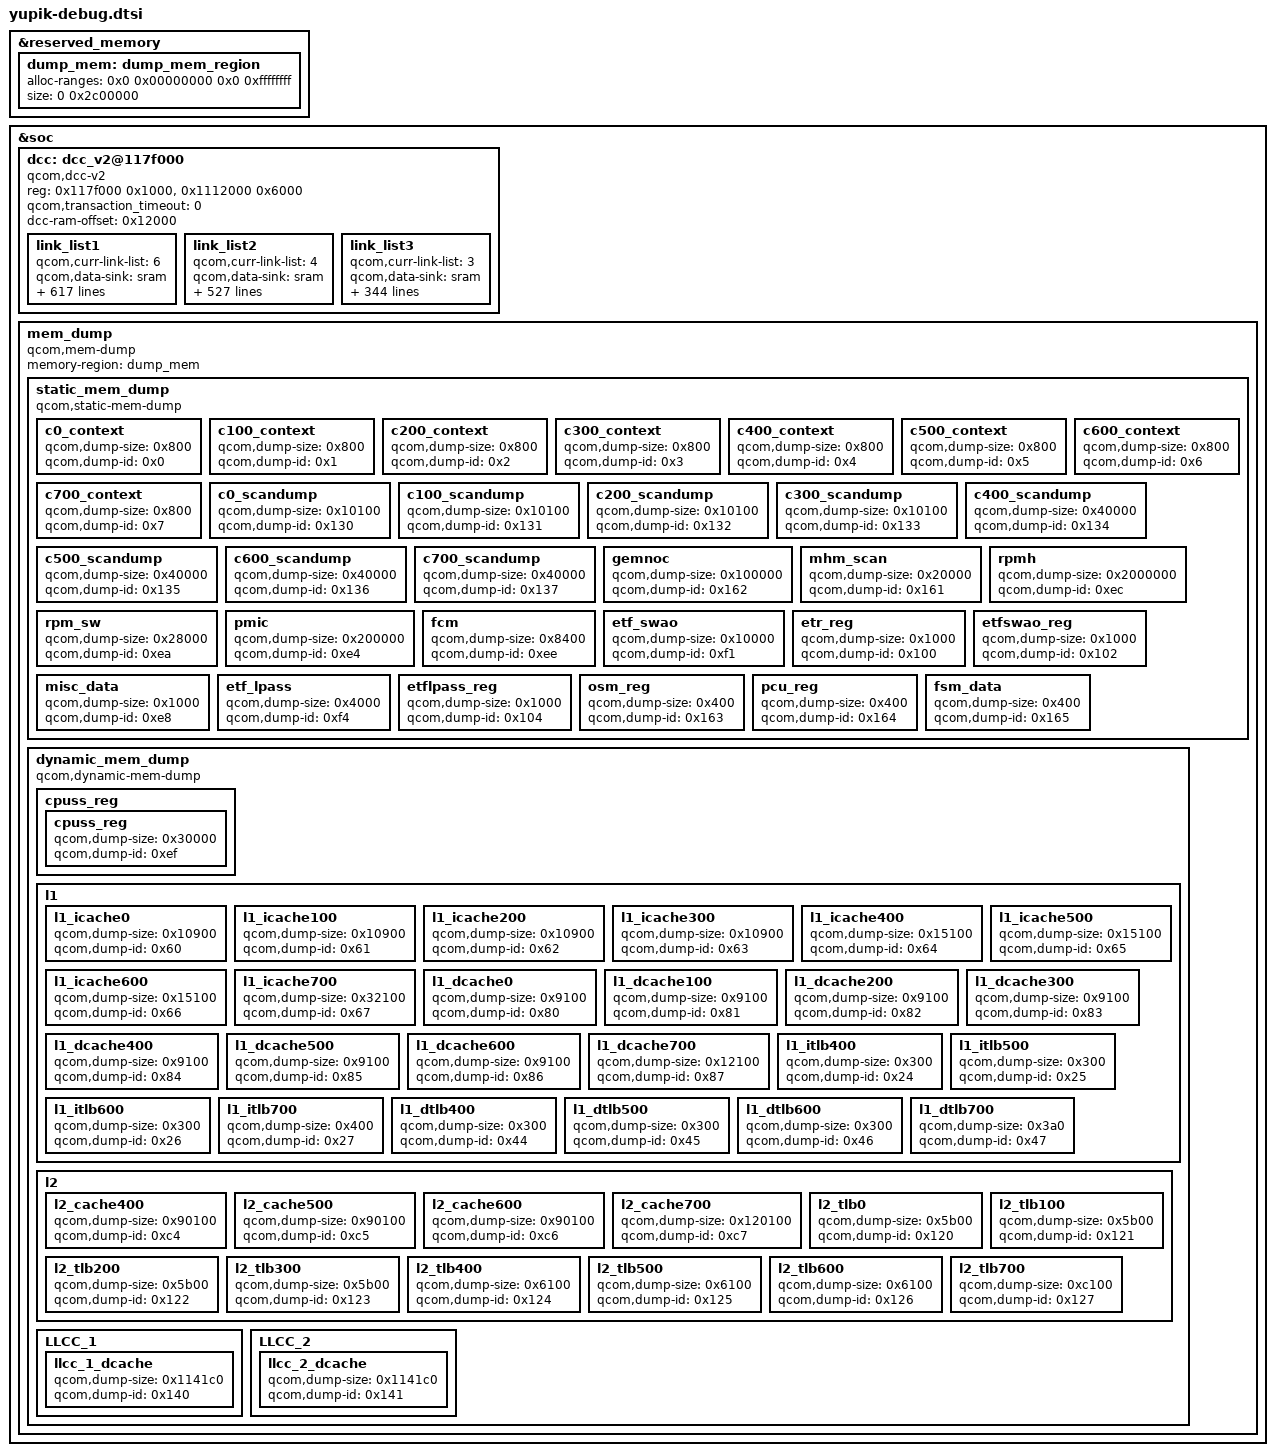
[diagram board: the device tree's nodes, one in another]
// SPDX-License-Identifier: BSD-3-Clause
/*
 * Copyright (c) Qualcomm Technologies, Inc. and/or its subsidiaries.
 */

#include <dt-bindings/soc/qcom,dcc_v2.h>

&reserved_memory {
	#address-cells = <2>;
	#size-cells = <2>;
	ranges;

	dump_mem: dump_mem_region {
		alloc-ranges = <0x0 0x00000000 0x0 0xffffffff>;
		size = <0 0x2c00000>;
	};
};

&soc {
	dcc: dcc_v2@117f000 {
		compatible = "qcom,dcc-v2";
		reg = <0x117f000 0x1000>,
		      <0x1112000 0x6000>;

		qcom,transaction_timeout = <0>;

		reg-names = "dcc-base", "dcc-ram-base";
		dcc-ram-offset = <0x12000>;

		link_list1 {
			qcom,curr-link-list = <6>;
			qcom,data-sink = "sram";
			qcom,link-list = <DCC_READ 0x18000010 1 0>,
				<DCC_READ 0x18000024 1 0>,
				<DCC_READ 0x18000038 6 0>,
				<DCC_READ 0x18010010 1 0>,
				<DCC_READ 0x18010024 1 0>,
				<DCC_READ 0x18010038 6 0>,
				<DCC_READ 0x18020010 1 0>,
				<DCC_READ 0x18020024 1 0>,
				<DCC_READ 0x18020038 6 0>,
				<DCC_READ 0x18030010 1 0>,
				<DCC_READ 0x18030024 1 0>,
				<DCC_READ 0x18030038 6 0>,
				<DCC_READ 0x18040010 1 0>,
				<DCC_READ 0x18040024 1 0>,
				<DCC_READ 0x18040038 6 0>,
				<DCC_READ 0x18050010 1 0>,
				<DCC_READ 0x18050024 1 0>,
				<DCC_READ 0x18050038 6 0>,
				<DCC_READ 0x18060010 1 0>,
				<DCC_READ 0x18060024 1 0>,
				<DCC_READ 0x18060038 6 0>,
				<DCC_READ 0x18070010 1 0>,
				<DCC_READ 0x18070024 1 0>,
				<DCC_READ 0x18070038 6 0>,
				<DCC_READ 0x18080010 1 0>,
				<DCC_READ 0x18080024 1 0>,
				<DCC_READ 0x18080038 6 0>,
				<DCC_READ 0x1808006c 5 0>,
				<DCC_READ 0x18080084 1 0>,
				<DCC_READ 0x180800f4 1 0>,
				<DCC_READ 0x180800f8 1 0>,
				<DCC_READ 0x180800fc 1 0>,
				<DCC_READ 0x18080100 12 0>,
				<DCC_READ 0x18080130 3 0>,
				<DCC_READ 0x18080158 1 0>,
				<DCC_READ 0x1808015c 1 0>,
				<DCC_READ 0x18080160 1 0>,
				<DCC_READ 0x18080164 1 0>,
				<DCC_READ 0x18080168 1 0>,
				<DCC_READ 0x18080170 1 0>,
				<DCC_READ 0x18080174 1 0>,
				<DCC_READ 0x18080188 1 0>,
				<DCC_READ 0x1808018c 1 0>,
				<DCC_READ 0x18080190 1 0>,
				<DCC_READ 0x18080194 1 0>,
				<DCC_READ 0x18080198 1 0>,
				<DCC_READ 0x180801ac 1 0>,
				<DCC_READ 0x180801b0 4 0>,
				<DCC_READ 0x180801c0 1 0>,
				<DCC_READ 0x180801c8 1 0>,
				<DCC_READ 0x180801f0 1 0>,
				<DCC_READ 0x18598020 1 0>,
				<DCC_READ 0x1859001c 1 0>,
				<DCC_READ 0x18590020 1 0>,
				<DCC_READ 0x1859002c 1 0>,
				<DCC_READ 0x18590064 1 0>,
				<DCC_READ 0x18590068 1 0>,
				<DCC_READ 0x1859006c 1 0>,
				<DCC_READ 0x18590070 3 0>,
				<DCC_READ 0x1859008c 1 0>,
				<DCC_READ 0x185900dc 1 0>,
				<DCC_READ 0x185900e8 1 0>,
				<DCC_READ 0x185900ec 1 0>,
				<DCC_READ 0x185900f0 1 0>,
				<DCC_READ 0x18590300 1 0>,
				<DCC_READ 0x1859030c 1 0>,
				<DCC_READ 0x18590320 1 0>,
				<DCC_READ 0x1859034c 1 0>,
				<DCC_READ 0x185903bc 1 0>,
				<DCC_READ 0x185903c0 1 0>,
				<DCC_READ 0x1859101c 1 0>,
				<DCC_READ 0x18591020 1 0>,
				<DCC_READ 0x1859102c 1 0>,
				<DCC_READ 0x18591064 1 0>,
				<DCC_READ 0x18591068 1 0>,
				<DCC_READ 0x1859106c 1 0>,
				<DCC_READ 0x18591070 1 0>,
				<DCC_READ 0x18591074 1 0>,
				<DCC_READ 0x18591078 1 0>,
				<DCC_READ 0x1859108c 1 0>,
				<DCC_READ 0x185910dc 1 0>,
				<DCC_READ 0x185910e8 1 0>,
				<DCC_READ 0x185910ec 1 0>,
				<DCC_READ 0x185910f0 1 0>,
				<DCC_READ 0x18591300 1 0>,
				<DCC_READ 0x1859130c 1 0>,
				<DCC_READ 0x18591320 1 0>,
				<DCC_READ 0x1859134c 1 0>,
				<DCC_READ 0x185913bc 1 0>,
				<DCC_READ 0x185913c0 1 0>,
				<DCC_READ 0x1859201c 1 0>,
				<DCC_READ 0x18592020 1 0>,
				<DCC_READ 0x1859202c 1 0>,
				<DCC_READ 0x18592064 1 0>,
				<DCC_READ 0x18592068 1 0>,
				<DCC_READ 0x1859206c 1 0>,
				<DCC_READ 0x18592070 1 0>,
				<DCC_READ 0x18592074 1 0>,
				<DCC_READ 0x18592078 1 0>,
				<DCC_READ 0x1859208c 1 0>,
				<DCC_READ 0x185920dc 1 0>,
				<DCC_READ 0x185920e8 1 0>,
				<DCC_READ 0x185920ec 1 0>,
				<DCC_READ 0x185920f0 1 0>,
				<DCC_READ 0x18592300 1 0>,
				<DCC_READ 0x1859230c 1 0>,
				<DCC_READ 0x18592320 1 0>,
				<DCC_READ 0x1859234c 1 0>,
				<DCC_READ 0x185923bc 1 0>,
				<DCC_READ 0x185923c0 1 0>,
				<DCC_READ 0x1859301c 1 0>,
				<DCC_READ 0x18593020 1 0>,
				<DCC_READ 0x18593064 1 0>,
				<DCC_READ 0x18593068 1 0>,
				<DCC_READ 0x1859306c 1 0>,
				<DCC_READ 0x18593070 1 0>,
				<DCC_READ 0x18593074 1 0>,
				<DCC_READ 0x18593078 1 0>,
				<DCC_READ 0x1859308c 1 0>,
				<DCC_READ 0x185930dc 1 0>,
				<DCC_READ 0x185930e8 1 0>,
				<DCC_READ 0x185930ec 1 0>,
				<DCC_READ 0x185930f0 1 0>,
				<DCC_READ 0x18593300 1 0>,
				<DCC_READ 0x1859330c 1 0>,
				<DCC_READ 0x18593320 1 0>,
				<DCC_READ 0x1859302c 1 0>,
				<DCC_READ 0x1859334c 1 0>,
				<DCC_READ 0x185933bc 1 0>,
				<DCC_READ 0x185933c0 1 0>,
				<DCC_READ 0x18300000 1 0>,
				<DCC_READ 0x1830000c 1 0>,
				<DCC_READ 0x18300018 1 0>,
				<DCC_READ 0x17c21000 2 0>,
				<DCC_READ 0x18393a84 2 0>,
				<DCC_READ 0x183a3a84 2 0>,
				<DCC_READ 0x18280000 2 0>,
				<DCC_READ 0x18282000 2 0>,
				<DCC_READ 0x18284000 2 0>,
				<DCC_READ 0x18286000 2 0>,
				<DCC_READ 0x18300000 1 0>,
				<DCC_READ 0x18200400 3 0>,
				<DCC_READ 0x18200038 1 0>,
				<DCC_READ 0x18200040 1 0>,
				<DCC_READ 0x18200048 1 0>,
				<DCC_READ 0x18220038 1 0>,
				<DCC_READ 0x18220040 1 0>,
				<DCC_READ 0x182200d0 1 0>,
				<DCC_READ 0x18200030 1 0>,
				<DCC_READ 0x18200010 1 0>,
				<DCC_READ 0x610100 11 0>,
				<DCC_READ 0x18000058 1 0>,
				<DCC_READ 0x1800005c 1 0>,
				<DCC_READ 0x18000060 1 0>,
				<DCC_READ 0x18000064 1 0>,
				<DCC_READ 0x1800006c 1 0>,
				<DCC_READ 0x180000f0 2 0>,
				<DCC_READ 0x18010058 1 0>,
				<DCC_READ 0x1801005c 1 0>,
				<DCC_READ 0x18010060 1 0>,
				<DCC_READ 0x18010064 1 0>,
				<DCC_READ 0x1801006c 1 0>,
				<DCC_READ 0x180100f0 2 0>,
				<DCC_READ 0x18020058 1 0>,
				<DCC_READ 0x1802005c 1 0>,
				<DCC_READ 0x18020060 1 0>,
				<DCC_READ 0x18020064 1 0>,
				<DCC_READ 0x1802006c 1 0>,
				<DCC_READ 0x180200f0 2 0>,
				<DCC_READ 0x18030058 1 0>,
				<DCC_READ 0x1803005c 1 0>,
				<DCC_READ 0x18030060 1 0>,
				<DCC_READ 0x18030064 1 0>,
				<DCC_READ 0x1803006c 1 0>,
				<DCC_READ 0x180300f0 2 0>,
				<DCC_READ 0x18040058 1 0>,
				<DCC_READ 0x1804005c 1 0>,
				<DCC_READ 0x18040060 1 0>,
				<DCC_READ 0x18040064 1 0>,
				<DCC_READ 0x1804006c 1 0>,
				<DCC_READ 0x180400f0 2 0>,
				<DCC_READ 0x18050058 1 0>,
				<DCC_READ 0x1805005c 1 0>,
				<DCC_READ 0x18050060 1 0>,
				<DCC_READ 0x18050064 1 0>,
				<DCC_READ 0x1805006c 1 0>,
				<DCC_READ 0x180500f0 2 0>,
				<DCC_READ 0x18060058 1 0>,
				<DCC_READ 0x1806005c 1 0>,
				<DCC_READ 0x18060060 1 0>,
				<DCC_READ 0x18060064 1 0>,
				<DCC_READ 0x1806006c 1 0>,
				<DCC_READ 0x180600f0 2 0>,
				<DCC_READ 0x18070058 1 0>,
				<DCC_READ 0x1807005c 1 0>,
				<DCC_READ 0x18070060 1 0>,
				<DCC_READ 0x18070064 1 0>,
				<DCC_READ 0x1807006c 1 0>,
				<DCC_READ 0x180700f0 2 0>,
				<DCC_READ 0x18101908 1 0>,
				<DCC_READ 0x18101c18 1 0>,
				<DCC_READ 0x18390810 1 0>,
				<DCC_READ 0x18390c50 1 0>,
				<DCC_READ 0x18390814 1 0>,
				<DCC_READ 0x18390c54 1 0>,
				<DCC_READ 0x18390818 1 0>,
				<DCC_READ 0x18390c58 1 0>,
				<DCC_READ 0x18393a84 2 0>,
				<DCC_READ 0x18100908 1 0>,
				<DCC_READ 0x18100c18 1 0>,
				<DCC_READ 0x183a0810 1 0>,
				<DCC_READ 0x183a0c50 1 0>,
				<DCC_READ 0x183a0814 1 0>,
				<DCC_READ 0x183a0c54 1 0>,
				<DCC_READ 0x183a0818 1 0>,
				<DCC_READ 0x183a0c58 1 0>,
				<DCC_READ 0x183a3a84 2 0>,
				<DCC_READ 0x18393500 1 0>,
				<DCC_READ 0x18393580 1 0>,
				<DCC_READ 0x183a3500 1 0>,
				<DCC_READ 0x183a3580 1 0>,
				<DCC_READ 0x18282000 4 0>,
				<DCC_READ 0x18282028 1 0>,
				<DCC_READ 0x18282038 1 0>,
				<DCC_READ 0x18282080 5 0>,
				<DCC_READ 0x18286000 4 0>,
				<DCC_READ 0x18286028 1 0>,
				<DCC_READ 0x18286038 1 0>,
				<DCC_READ 0x18286080 5 0>,
				<DCC_READ 0x0c201244 1 0>,
				<DCC_READ 0x0c202244 1 0>,
				<DCC_READ 0x18300000 1 0>,
				<DCC_READ 0x1829208c 1 0>,
				<DCC_READ 0x18292098 1 0>,
				<DCC_READ 0x18292098 1 0>,
				<DCC_READ 0x1829608c 1 0>,
				<DCC_READ 0x18296098 1 0>,
				<DCC_READ 0x18296098 1 0>,
				<DCC_READ 0x00784184 1 0>,
				<DCC_READ 0x9103008 1 0>,
				<DCC_LOOP 0x5 0 0>,
				<DCC_READ 0x9103010 1 0>,
				<DCC_READ 0x9103014 1 0>,
				<DCC_LOOP 0x1 0 0>,
				<DCC_READ 0x9103408 1 0>,
				<DCC_LOOP 0x5 0 0>,
				<DCC_READ 0x9103410 1 0>,
				<DCC_READ 0x9103414 1 0>,
				<DCC_LOOP 0x1 0 0>,
				<DCC_READ 0x9143008 1 0>,
				<DCC_LOOP 0x5 0 0>,
				<DCC_READ 0x9143010 1 0>,
				<DCC_READ 0x9143014 1 0>,
				<DCC_LOOP 0x1 0 0>,
				<DCC_READ 0x9143408 1 0>,
				<DCC_LOOP 0x5 0 0>,
				<DCC_READ 0x9143410 1 0>,
				<DCC_READ 0x9143414 1 0>,
				<DCC_LOOP 0x1 0 0>,
				<DCC_READ 0x91b0008 1 0>,
				<DCC_LOOP 0x3 0 0>,
				<DCC_READ 0x91b0010 1 0>,
				<DCC_READ 0x91b0014 1 0>,
				<DCC_LOOP 0x1 0 0>,
				<DCC_READ 0x91b1008 1 0>,
				<DCC_LOOP 0x10 0 0>,
				<DCC_READ 0x91b1010 1 0>,
				<DCC_READ 0x91b1014 1 0>,
				<DCC_LOOP 0x1 0 0>,
				<DCC_READ 0x9101808 1 0>,
				<DCC_READ 0x910180c 1 0>,
				<DCC_WRITE 0x9101828 0x00000001 1>,
				<DCC_LOOP 0x41 0 0>,
				<DCC_READ 0x9101810 1 0>,
				<DCC_READ 0x9101814 1 0>,
				<DCC_READ 0x9101818 1 0>,
				<DCC_READ 0x910181c 1 0>,
				<DCC_LOOP 0x1 0 0>,
				<DCC_READ 0x9141808 1 0>,
				<DCC_READ 0x914180c 1 0>,
				<DCC_WRITE 0x9141828 0x00000001 1>,
				<DCC_LOOP 0x41 0 0>,
				<DCC_READ 0x9141810 1 0>,
				<DCC_READ 0x9141814 1 0>,
				<DCC_READ 0x9141818 1 0>,
				<DCC_READ 0x914181c 1 0>,
				<DCC_LOOP 0x1 0 0>,
				<DCC_READ 0x91a8008 1 0>,
				<DCC_READ 0x91a800c 1 0>,
				<DCC_WRITE 0x91a8028 0x00000001 1>,
				<DCC_LOOP 0x11 0 0>,
				<DCC_READ 0x91a8010 1 0>,
				<DCC_READ 0x91a8014 1 0>,
				<DCC_READ 0x91a8018 1 0>,
				<DCC_READ 0x91a801c 1 0>,
				<DCC_LOOP 0x1 0 0>,
				<DCC_READ 0x91a8808 1 0>,
				<DCC_READ 0x91a880c 1 0>,
				<DCC_WRITE 0x91a8828 0x00000001 1>,
				<DCC_LOOP 0x11 0 0>,
				<DCC_READ 0x91a8810 1 0>,
				<DCC_READ 0x91a8814 1 0>,
				<DCC_READ 0x91a8818 1 0>,
				<DCC_READ 0x91a881c 1 0>,
				<DCC_LOOP 0x1 0 0>,
				<DCC_READ 0x9100000 1 0>,
				<DCC_READ 0x9100008 1 0>,
				<DCC_READ 0x910000c 1 0>,
				<DCC_READ 0x9140000 1 0>,
				<DCC_READ 0x9140008 1 0>,
				<DCC_READ 0x914000c 1 0>,
				<DCC_READ 0x9180000 1 0>,
				<DCC_READ 0x9180008 1 0>,
				<DCC_READ 0x918000c 1 0>,
				<DCC_READ 0x9180404 1 0>,
				<DCC_READ 0x9180408 1 0>,
				<DCC_READ 0x918040c 1 0>,
				<DCC_READ 0x9181010 1 0>,
				<DCC_READ 0x9181020 8 0>,
				<DCC_READ 0x91e1048 1 0>,
				<DCC_READ 0x9121010 1 0>,
				<DCC_READ 0x9122010 1 0>,
				<DCC_READ 0x9123010 1 0>,
				<DCC_READ 0x9125010 1 0>,
				<DCC_READ 0x9161010 1 0>,
				<DCC_READ 0x9162010 1 0>,
				<DCC_READ 0x9163010 1 0>,
				<DCC_READ 0x9165010 1 0>,
				<DCC_READ 0x91cf010 1 0>,
				<DCC_READ 0x91d0010 1 0>,
				<DCC_READ 0x91d1010 1 0>,
				<DCC_READ 0x91d2010 1 0>,
				<DCC_READ 0x91d3010 1 0>,
				<DCC_READ 0x91d4010 1 0>,
				<DCC_READ 0x91d5010 1 0>,
				<DCC_READ 0x91d6010 1 0>,
				<DCC_READ 0x91d7010 1 0>,
				<DCC_READ 0x9101408 1 0>,
				<DCC_READ 0x9141410 1 0>,
				<DCC_READ 0x9100810 1 0>,
				<DCC_READ 0x9140810 1 0>,
				<DCC_READ 0x9100820 1 0>,
				<DCC_READ 0x9140820 1 0>,
				<DCC_READ 0x9100828 1 0>,
				<DCC_READ 0x910082c 1 0>,
				<DCC_READ 0x9140828 1 0>,
				<DCC_READ 0x914082c 1 0>,
				<DCC_READ 0x0c222004 1 0>,
				<DCC_READ 0x0c263014 1 0>,
				<DCC_READ 0x0c2630e0 1 0>,
				<DCC_READ 0x0c2630ec 1 0>,
				<DCC_READ 0x0c2630a0 16 0>,
				<DCC_READ 0x0c2630e8 1 0>,
				<DCC_READ 0x0c26313c 1 0>,
				<DCC_READ 0x0c223004 1 0>,
				<DCC_READ 0x0c265014 1 0>,
				<DCC_READ 0x0c2650e0 1 0>,
				<DCC_READ 0x0c2650ec 1 0>,
				<DCC_READ 0x0c2650a0 16 0>,
				<DCC_READ 0x0c2650e8 1 0>,
				<DCC_READ 0x0c26513c 1 0>,
				<DCC_READ 0xc410000 1 0>,
				<DCC_READ 0xc40af04 1 0>,
				<DCC_READ 0xc40af10 1 0>,
				<DCC_READ 0xc40a000 1 0>,
				<DCC_READ 0xc40a018 1 0>,
				<DCC_READ 0xc40a028 1 0>,
				<DCC_READ 0xc40a02c 1 0>,
				<DCC_READ 0xc40a100 1 0>,
				<DCC_READ 0xc2a22fc 1 0>,
				<DCC_READ 0xc2a2300 1 0>,
				<DCC_READ 0xc2a2304 1 0>,
				<DCC_READ 0xc440200 1 0>,
				<DCC_READ 0xc440204 1 0>,
				<DCC_READ 0xc442200 1 0>,
				<DCC_READ 0xc442204 1 0>,
				<DCC_READ 0xc442208 1 0>,
				<DCC_READ 0xc44220c 1 0>,
				<DCC_READ 0x3d9100c 1 0>,
				<DCC_READ 0x3d91010 2 0>,
				<DCC_READ 0x3d9106c 3 0>,
				<DCC_READ 0x3d91004 1 0>,
				<DCC_READ 0x3d91054 3 0>,
				<DCC_READ 0x3d91060 2 0>,
				<DCC_READ 0x3d91070 2 0>,
				<DCC_READ 0x3d91080 3 0>,
				<DCC_READ 0x3d91078 2 0>,
				<DCC_READ 0x3d9108c 1 0>,
				<DCC_READ 0x3d91090 1 0>,
				<DCC_READ 0x3d91098 2 0>,
				<DCC_READ 0x3d910a4 2 0>,
				<DCC_READ 0x3d910f0 2 0>,
				<DCC_READ 0x3d91100 1 0>,
				<DCC_READ 0x3d91118 1 0>,
				<DCC_READ 0x3d91164 2 0>,
				<DCC_READ 0x3d91170 1 0>,
				<DCC_READ 0x3d91178 1 0>,
				<DCC_READ 0x3d91204 1 0>,
				<DCC_READ 0x3d9120c 1 0>,
				<DCC_READ 0x3d98024 1 0>,
				<DCC_READ 0x3d9802c 1 0>,
				<DCC_READ 0x3d98030 1 0>,
				<DCC_READ 0x3d92000 2 0>,
				<DCC_READ 0x3d93000 2 0>,
				<DCC_READ 0x3d95000 2 0>,
				<DCC_READ 0x3d96000 2 0>,
				<DCC_READ 0x3d97000 2 0>,
				<DCC_READ 0x119000 1 0>,
				<DCC_READ 0x11903c 1 0>,
				<DCC_READ 0x171004 2 0>,
				<DCC_READ 0x17100c 1 0>,
				<DCC_READ 0x171014 1 0>,
				<DCC_READ 0x171018 1 0>,
				<DCC_READ 0x171154 1 0>,
				<DCC_READ 0x171158 1 0>,
				<DCC_READ 0x17115c 1 0>,
				<DCC_READ 0x17a04c 1 0>,
				<DCC_READ 0x17b000 1 0>,
				<DCC_READ 0x17b03c 1 0>,
				<DCC_READ 0x17c000 1 0>,
				<DCC_READ 0x17c03c 1 0>,
				<DCC_READ 0x17d000 1 0>,
				<DCC_READ 0x17d03c 1 0>,
				<DCC_READ 0x17e000 1 0>,
				<DCC_READ 0x17e03c 1 0>,
				<DCC_READ 0x187000 1 0>,
				<DCC_READ 0x18703c 1 0>,
				<DCC_READ 0x3d91534 1 0>,
				<DCC_READ 0x3d002b4 1 0>,
				<DCC_READ 0x3d00410 2 0>,
				<DCC_READ 0x3d00818 1 0>,
				<DCC_READ 0x3d7e220 2 0>,
				<DCC_READ 0x1680B00 1 0>,
				<DCC_READ 0x1680008 1 0>,
				<DCC_READ 0x1680010 1 0>,
				<DCC_READ 0x1680020 8 0>,
				<DCC_READ 0x1680248 1 0>,
				<DCC_READ 0x1680b00 6 0>,
				<DCC_READ 0x16e4008 1 0>,
				<DCC_LOOP 4 0 0>,
				<DCC_READ 0x16e4010 1 0>,
				<DCC_READ 0x16e4014 1 0>,
				<DCC_LOOP 1 0 0>,
				<DCC_READ 0x1706208 1 0>,
				<DCC_LOOP 4 0 0>,
				<DCC_READ 0x1706210 1 0>,
				<DCC_READ 0x1706214 1 0>,
				<DCC_LOOP 1 0 0>,
				<DCC_READ 0x16e0000 1 0>,
				<DCC_READ 0x16e0010 1 0>,
				<DCC_READ 0x16e0008 1 0>,
				<DCC_READ 0x16e0020 8 0>,
				<DCC_READ 0x16e5048 1 0>,
				<DCC_READ 0x16e5248 1 0>,
				<DCC_READ 0x16e5448 1 0>,
				<DCC_READ 0x16e5100 5 0>,
				<DCC_READ 0x16e5300 2 0>,
				<DCC_READ 0x16e5500 2 0>,
				<DCC_READ 0x1700000 1 0>,
				<DCC_READ 0x1700008 1 0>,
				<DCC_READ 0x1700010 1 0>,
				<DCC_READ 0x1700020 8 0>,
				<DCC_READ 0x170b100 5 0>,
				<DCC_READ 0x170b048 1 0>,
				<DCC_READ 0x100000 15 0>,
				<DCC_READ 0x101000 15 0>,
				<DCC_READ 0x176000 15 0>,
				<DCC_READ 0x174000 15 0>,
				<DCC_READ 0x113000 15 0>,
				<DCC_READ 0x11a000 15 0>,
				<DCC_READ 0x11c000 15 0>,
				<DCC_READ 0x11c048 3 0>,
				<DCC_READ 0x11e000 15 0>,
				<DCC_READ 0x10401c 1 0>,
				<DCC_READ 0x105074 1 0>,
				<DCC_READ 0x183024 1 0>,
				<DCC_READ 0x109050 1 0>,
				<DCC_READ 0x123020 1 0>,
				<DCC_READ 0x117024 1 0>,
				<DCC_READ 0x117154 1 0>,
				<DCC_READ 0x117284 1 0>,
				<DCC_READ 0x1173b4 1 0>,
				<DCC_READ 0x1174e4 1 0>,
				<DCC_READ 0x117614 1 0>,
				<DCC_READ 0x117744 1 0>,
				<DCC_READ 0x117874 1 0>,
				<DCC_READ 0x118024 1 0>,
				<DCC_READ 0x118154 1 0>,
				<DCC_READ 0x118284 1 0>,
				<DCC_READ 0x1183b4 1 0>,
				<DCC_READ 0x1184e4 1 0>,
				<DCC_READ 0x118614 1 0>,
				<DCC_READ 0x118744 1 0>,
				<DCC_READ 0x118874 1 0>,
				<DCC_READ 0x129020 1 0>,
				<DCC_READ 0x11d020 1 0>,
				<DCC_READ 0x134024 1 0>,
				<DCC_READ 0x141024 1 0>,
				<DCC_READ 0x14415c 1 0>,
				<DCC_READ 0x14504c 1 0>,
				<DCC_READ 0x18903c 1 0>,
				<DCC_READ 0x151000 1 0>,
				<DCC_READ 0x151008 1 0>,
				<DCC_READ 0x151010 1 0>,
				<DCC_READ 0x152000 1 0>,
				<DCC_READ 0x152008 1 0>,
				<DCC_READ 0x152010 1 0>,
				<DCC_READ 0x153020 1 0>,
				<DCC_READ 0x153028 1 0>,
				<DCC_READ 0x153030 1 0>,
				<DCC_READ 0x155000 1 0>,
				<DCC_READ 0x155008 1 0>,
				<DCC_READ 0x155010 1 0>,
				<DCC_READ 0x15b000 1 0>,
				<DCC_READ 0x15b008 1 0>,
				<DCC_READ 0x15b010 1 0>,
				<DCC_READ 0x157000 1 0>,
				<DCC_READ 0x157008 1 0>,
				<DCC_READ 0x157010 1 0>,
				<DCC_READ 0x135020 1 0>,
				<DCC_READ 0x135028 1 0>,
				<DCC_READ 0x135030 1 0>,
				<DCC_READ 0x156000 1 0>,
				<DCC_READ 0x156008 1 0>,
				<DCC_READ 0x156010 1 0>,
				<DCC_READ 0x15a000 1 0>,
				<DCC_READ 0x15a008 1 0>,
				<DCC_READ 0x15a010 1 0>,
				<DCC_READ 0x190004 1 0>,
				<DCC_READ 0x109008 1 0>,
				<DCC_READ 0x190010 1 0>,
				<DCC_READ 0x190020 1 0>,
				<DCC_READ 0x190028 1 0>,
				<DCC_READ 0x109010 1 0>,
				<DCC_READ 0x109018 1 0>,
				<DCC_READ 0x109018 1 0>,
				<DCC_READ 0x109020 1 0>,
				<DCC_READ 0x18d080 1 0>,
				<DCC_READ 0x145014 1 0>,
				<DCC_READ 0x14501c 1 0>,
				<DCC_READ 0x183004 1 0>,
				<DCC_READ 0x183008 1 0>,
				<DCC_READ 0x183140 1 0>,
				<DCC_READ 0x171158 2 0>,
				<DCC_READ 0x109004 3 0>,
				<DCC_READ 0x109160 1 0>,
				<DCC_READ 0x109468 1 0>,
				<DCC_READ 0x10f004 3 0>,
				<DCC_READ 0x145000 3 0>,
				<DCC_READ 0x16b004 3 0>,
				<DCC_READ 0x18d004 3 0>,
				<DCC_READ 0x177004 3 0>,
				<DCC_READ 0x189004 3 0>,
				<DCC_READ 0x153000 9 0>,
				<DCC_READ 0x135000 9 0>,
				<DCC_READ 0x106100 1 0>,
				<DCC_READ 0x147004 1 0>,
				<DCC_READ 0x17b000 1 0>,
				<DCC_READ 0x17b004 1 0>,
				<DCC_READ 0x17b008 1 0>,
				<DCC_READ 0x17b00c 1 0>,
				<DCC_READ 0x17b010 1 0>,
				<DCC_READ 0x17b014 1 0>,
				<DCC_READ 0x17b018 1 0>,
				<DCC_READ 0x17b01c 1 0>,
				<DCC_READ 0x17b020 1 0>,
				<DCC_READ 0x17b024 1 0>,
				<DCC_READ 0x17b028 1 0>,
				<DCC_READ 0x17b02c 1 0>,
				<DCC_READ 0x17b03c 1 0>,
				<DCC_READ 0x17b040 1 0>,
				<DCC_READ 0x17b044 1 0>,
				<DCC_READ 0x17b048 1 0>,
				<DCC_READ 0x17b04c 1 0>,
				<DCC_READ 0x17b050 1 0>,
				<DCC_READ 0x17b054 1 0>,
				<DCC_READ 0x17b058 1 0>,
				<DCC_READ 0x17b05c 1 0>,
				<DCC_READ 0x17b060 1 0>,
				<DCC_READ 0x17b064 1 0>,
				<DCC_READ 0x17b068 1 0>,
				<DCC_READ 0x17c000 1 0>,
				<DCC_READ 0x17c004 1 0>,
				<DCC_READ 0x17c008 1 0>,
				<DCC_READ 0x17c00c 1 0>,
				<DCC_READ 0x17c010 1 0>,
				<DCC_READ 0x17c014 1 0>,
				<DCC_READ 0x17c018 1 0>,
				<DCC_READ 0x17c01c 1 0>,
				<DCC_READ 0x17c020 1 0>,
				<DCC_READ 0x17c024 1 0>,
				<DCC_READ 0x17c028 1 0>,
				<DCC_READ 0x17c02c 1 0>,
				<DCC_READ 0x17c03c 1 0>,
				<DCC_READ 0x17c040 1 0>,
				<DCC_READ 0x17c044 1 0>,
				<DCC_READ 0x17c048 1 0>,
				<DCC_READ 0x17c04c 1 0>,
				<DCC_READ 0x17c050 1 0>,
				<DCC_READ 0x17c054 1 0>,
				<DCC_READ 0x17c058 1 0>,
				<DCC_READ 0x17c05c 1 0>,
				<DCC_READ 0x17c060 1 0>,
				<DCC_READ 0x17c064 1 0>,
				<DCC_READ 0x17c068 1 0>,
				<DCC_READ 0x153124 1 0>,
				<DCC_READ 0x156124 1 0>,
				<DCC_READ 0x1453a4 1 0>,
				<DCC_READ 0x182884 1 0>,
				<DCC_READ 0x145384 1 0>,
				<DCC_READ 0xc2a0000 15 0>,
				<DCC_READ 0xc2a1000 15 0>,
				<DCC_READ 0x17101c 1 0>,
				<DCC_READ 0x171020 1 0>,
				<DCC_READ 0x14401c 1 0>,
				<DCC_READ 0x144020 1 0>,
				<DCC_READ 0x183010 1 0>,
				<DCC_READ 0x183014 1 0>,
				<DCC_READ 0x18a160 1 0>,
				<DCC_READ 0x18a164 1 0>,
				<DCC_READ 0x18a004 1 0>,
				<DCC_READ 0x18a01c 1 0>,
				<DCC_READ 0x18a020 1 0>,
				<DCC_READ 0x18a024 1 0>,
				<DCC_READ 0x19d004 1 0>,
				<DCC_READ 0x19d008 1 0>,
				<DCC_READ 0x196100 1 0>,
				<DCC_READ 0x10003c 1 0>,
				<DCC_READ 0x10103c 1 0>,
				<DCC_READ 0x10203c 1 0>,
				<DCC_READ 0x10303c 1 0>,
				<DCC_READ 0x11303c 1 0>,
				<DCC_READ 0x11a03c 1 0>,
				<DCC_READ 0x11c03c 1 0>,
				<DCC_READ 0x17403c 1 0>,
				<DCC_READ 0x17603c 1 0>,
				<DCC_READ 0x11e03c 1 0>,
				<DCC_READ 0xbbf0004 12 0>,
				<DCC_READ 0xbbf0800 12 0>,
				<DCC_READ 0xbbf0004 12 0>,
				<DCC_READ 0xbbf0800 12 0>;
		};

		link_list2 {
			qcom,curr-link-list = <4>;
			qcom,data-sink = "sram";
			qcom,link-list = <DCC_READ 0x01510008 1 0>,
				<DCC_LOOP 9 0 0>,
				<DCC_READ 0x151d010 1 0>,
				<DCC_READ 0x151d014 1 0>,
				<DCC_LOOP 1 0 0>,
				<DCC_LOOP 9 0 0>,
				<DCC_READ 0x1506010 1 0>,
				<DCC_READ 0x1506014 1 0>,
				<DCC_LOOP 1 0 0>,
				<DCC_READ 0x151d208 1 0>,
				<DCC_READ 0x1507008 1 0>,
				<DCC_LOOP 2 0 0>,
				<DCC_READ 0x151d210 1 0>,
				<DCC_READ 0x151d214 1 0>,
				<DCC_LOOP 1 0 0>,
				<DCC_LOOP 2 0 0>,
				<DCC_READ 0x1507010 1 0>,
				<DCC_READ 0x1507014 1 0>,
				<DCC_LOOP 1 0 0>,
				<DCC_READ 0x151d308 1 0>,
				<DCC_READ 0x1509008 1 0>,
				<DCC_LOOP 3 0 0>,
				<DCC_READ 0x1509010 1 0>,
				<DCC_READ 0x1509014 1 0>,
				<DCC_LOOP 1 0 0>,
				<DCC_LOOP 3 0 0>,
				<DCC_READ 0x151d310 1 0>,
				<DCC_READ 0x151d314 1 0>,
				<DCC_LOOP 1 0 0>,
				<DCC_READ 0x01514008 1 0>,
				<DCC_LOOP 3 0 0>,
				<DCC_READ 0x01514010 1 0>,
				<DCC_LOOP 1 0 0>,
				<DCC_READ 0x1500000 1 0>,
				<DCC_READ 0x1510000 1 0>,
				<DCC_READ 0x1500010 1 0>,
				<DCC_READ 0x1510010 1 0>,
				<DCC_READ 0x1500020 8 0>,
				<DCC_READ 0x1510020 8 0>,
				<DCC_READ 0x1511048 1 0>,
				<DCC_READ 0x1501048 2 0>,
				<DCC_READ 0x1501058 1 0>,
				<DCC_READ 0x1501248 1 0>,
				<DCC_READ 0x1511248 1 0>,
				<DCC_READ 0x1501248 1 0>,
				<DCC_READ 0x1511b00 1 0>,
				<DCC_READ 0x151e100 1 0>,
				<DCC_READ 0x150b100 1 0>,
				<DCC_READ 0xec80004 1 0>,
				<DCC_READ 0xec80058 1 0>,
				<DCC_READ 0xec80060 8 0>,
				<DCC_READ 0xec800a0 8 0>,
				<DCC_READ 0xec800c0 16 0>,
				<DCC_READ 0xec80100 16 0>,
				<DCC_READ 0x634008 1 0>,
				<DCC_READ 0x634f00 8 0>,
				<DCC_READ 0x635560 1 0>,
				<DCC_READ 0x635570 1 0>,
				<DCC_READ 0x635580 1 0>,
				<DCC_READ 0x635590 1 0>,
				<DCC_READ 0x6355a0 4 0>,
				<DCC_READ 0x635600 1 0>,
				<DCC_READ 0x635610 1 0>,
				<DCC_READ 0x636008 1 0>,
				<DCC_READ 0x636f00 8 0>,
				<DCC_READ 0x637560 1 0>,
				<DCC_READ 0x637570 1 0>,
				<DCC_READ 0x637580 1 0>,
				<DCC_READ 0x637590 1 0>,
				<DCC_READ 0x6375a0 4 0>,
				<DCC_READ 0x637600 1 0>,
				<DCC_READ 0x637610 1 0>,
				<DCC_READ 0x18370220 2 0>,
				<DCC_READ 0x183702a0 2 0>,
				<DCC_READ 0x183704a0 12 0>,
				<DCC_READ 0x18370520 1 0>,
				<DCC_READ 0x18370588 1 0>,
				<DCC_READ 0x18370d10 12 0>,
				<DCC_READ 0x18370f90 10 0>,
				<DCC_READ 0x18371010 10 0>,
				<DCC_READ 0x18371a10 8 0>,
				<DCC_READ 0x183784a0 12 0>,
				<DCC_READ 0x18378520 1 0>,
				<DCC_READ 0x18378588 1 0>,
				<DCC_READ 0x18378d10 8 0>,
				<DCC_READ 0x18378f90 6 0>,
				<DCC_READ 0x18379010 6 0>,
				<DCC_READ 0x18379a10 4 0>,
				<DCC_READ 0xa310220 3 0>,
				<DCC_READ 0xa3102a0 3 0>,
				<DCC_READ 0xa3104a0 6 0>,
				<DCC_READ 0xa310520 1 0>,
				<DCC_READ 0xa310588 1 0>,
				<DCC_READ 0xa310d10 8 0>,
				<DCC_READ 0xa310f90 6 0>,
				<DCC_READ 0xa311010 6 0>,
				<DCC_READ 0xa311a10 3 0>,
				<DCC_READ 0x17a00104 29 0>,
				<DCC_READ 0x17a00204 29 0>,
				<DCC_READ 0x01741008 1 0>,
				<DCC_LOOP 9 0 0>,
				<DCC_READ 0x01741010 1 0>,
				<DCC_READ 0x01741014 1 0>,
				<DCC_LOOP 1 0 0>,
				<DCC_READ 0x1740000 1 0>,
				<DCC_READ 0x1740008 1 0>,
				<DCC_READ 0x1740010 1 0>,
				<DCC_READ 0x1740020 8 0>,
				<DCC_READ 0x174b048 1 0>,
				<DCC_READ 0x174b100 8 0>,
				<DCC_READ 0x90e0000 1 0>,
				<DCC_READ 0x90e0008 1 0>,
				<DCC_READ 0x90e0010 1 0>,
				<DCC_READ 0x90e0020 8 0>,
				<DCC_READ 0x90e0248 1 0>,
				<DCC_READ 0x90e3100 1 0>,
				<DCC_READ 0x90e4100 7 0>,
				<DCC_READ 0x1750010 1 0>,
				<DCC_READ 0x1750190 1 0>,
				<DCC_READ 0x1751010 1 0>,
				<DCC_READ 0x1752010 1 0>,
				<DCC_READ 0x1754010 1 0>,
				<DCC_READ 0x1755010 1 0>,
				<DCC_READ 0x1756010 1 0>,
				<DCC_READ 0x1758010 1 0>,
				<DCC_READ 0x1758090 1 0>,
				<DCC_READ 0x1759010 1 0>,
				<DCC_READ 0x175a010 1 0>,
				<DCC_READ 0x175c010 1 0>,
				<DCC_READ 0x175d010 1 0>,
				<DCC_READ 0x175e010 1 0>,
				<DCC_READ 0x0b201020 2 0>,
				<DCC_READ 0x0b200010 4 0>,
				<DCC_READ 0x0b220010 4 0>,
				<DCC_READ 0x0b200900 4 0>,
				<DCC_READ 0x0b220900 4 0>,
				<DCC_READ 0x0b201030 1 0>,
				<DCC_READ 0x0b201204 1 0>,
				<DCC_READ 0x0b201218 1 0>,
				<DCC_READ 0x0b20122c 1 0>,
				<DCC_READ 0x0b201240 1 0>,
				<DCC_READ 0x0b201254 1 0>,
				<DCC_READ 0x0b201208 1 0>,
				<DCC_READ 0x0b20121c 1 0>,
				<DCC_READ 0x0b201230 1 0>,
				<DCC_READ 0x0b201244 1 0>,
				<DCC_READ 0x0b201258 1 0>,
				<DCC_READ 0x0b204510 1 0>,
				<DCC_READ 0x0b204514 1 0>,
				<DCC_READ 0x0b204520 1 0>,
				<DCC_READ 0x0b211024 1 0>,
				<DCC_READ 0x0b221024 1 0>,
				<DCC_READ 0x0b231024 1 0>,
				<DCC_READ 0x18220010 1 0>,
				<DCC_READ 0x18220030 1 0>,
				<DCC_READ 0x182200d0 1 0>,
				<DCC_READ 0x18220408 1 0>,
				<DCC_READ 0x18230408 1 0>,
				<DCC_READ 0x17e00434 1 0>,
				<DCC_READ 0x17e0043c 2 0>,
				<DCC_READ 0x17c00038 2 0>,
				<DCC_READ 0x17c00438 1 0>,
				<DCC_READ 0x17e0041c 1 0>,
				<DCC_READ 0x17e00420 1 0>,
				<DCC_READ 0x17e00404 1 0>,
				<DCC_READ 0xc220000 2 0>,
				<DCC_READ 0xc230000 6 0>,
				<DCC_READ 0xc260008 1 0>,
				<DCC_READ 0x18598014 1 0>,
				<DCC_READ 0x4d8634 1 0>,
				<DCC_READ 0x4d8834 1 0>,
				<DCC_READ 0x418620 1 0>,
				<DCC_READ 0x418820 1 0>,
				<DCC_READ 0x9084208 1 0>,
				<DCC_READ 0x9084204 1 0>,
				<DCC_READ 0x9084108 1 0>,
				<DCC_READ 0x90841c0 1 0>,
				<DCC_READ 0x10c034 1 0>,
				<DCC_READ 0x10c038 1 0>,
				<DCC_READ 0x144018 1 0>,
				<DCC_WRITE 0x90841c0 0x1 0>,
				<DCC_WRITE 0x10c034 0x1 0>,
				<DCC_WRITE 0x10c038 0x1 0>,
				<DCC_WRITE 0x144018 0x1 0>,
				<DCC_READ 0x9050078 1 0>,
				<DCC_READ 0x9050110 8 0>,
				<DCC_READ 0x9080058 2 0>,
				<DCC_READ 0x90800c8 1 0>,
				<DCC_READ 0x90800d4 1 0>,
				<DCC_READ 0x90800e0 1 0>,
				<DCC_READ 0x90800fc 1 0>,
				<DCC_READ 0x9084030 1 0>,
				<DCC_READ 0x9084038 2 0>,
				<DCC_READ 0x90840e4 1 0>,
				<DCC_READ 0x90840f4 1 0>,
				<DCC_READ 0x9084104 2 0>,
				<DCC_READ 0x9084198 1 0>,
				<DCC_READ 0x9084804 1 0>,
				<DCC_READ 0x908480c 1 0>,
				<DCC_READ 0x9084844 1 0>,
				<DCC_READ 0x9084850 2 0>,
				<DCC_READ 0x9084860 3 0>,
				<DCC_READ 0x9084888 1 0>,
				<DCC_READ 0x908488c 1 0>,
				<DCC_READ 0x908409c 1 0>,
				<DCC_READ 0x90840a0 1 0>,
				<DCC_READ 0x908426c 1 0>,
				<DCC_READ 0x908439c 1 0>,
				<DCC_READ 0x9085124 1 0>,
				<DCC_READ 0x9085134 1 0>,
				<DCC_READ 0x9085138 1 0>,
				<DCC_READ 0x9084840 1 0>,
				<DCC_READ 0x9084834 1 0>,
				<DCC_READ 0x9085124 1 0>,
				<DCC_READ 0x90ba280 1 0>,
				<DCC_READ 0x90ba288 7 0>,
				<DCC_READ 0x9258610 4 0>,
				<DCC_READ 0x92d8610 4 0>,
				<DCC_READ 0x9220344 8 0>,
				<DCC_READ 0x9220370 6 0>,
				<DCC_READ 0x9220480 1 0>,
				<DCC_READ 0x9222400 1 0>,
				<DCC_READ 0x922240c 1 0>,
				<DCC_READ 0x9223214 2 0>,
				<DCC_READ 0x9223220 3 0>,
				<DCC_READ 0x9223308 1 0>,
				<DCC_READ 0x9223318 1 0>,
				<DCC_READ 0x9232100 1 0>,
				<DCC_READ 0x9236040 6 0>,
				<DCC_READ 0x92360b0 1 0>,
				<DCC_READ 0x923a004 4 0>,
				<DCC_READ 0x923e030 2 0>,
				<DCC_READ 0x9241000 1 0>,
				<DCC_READ 0x9242028 1 0>,
				<DCC_READ 0x9242044 3 0>,
				<DCC_READ 0x9242070 1 0>,
				<DCC_READ 0x9248030 1 0>,
				<DCC_READ 0x9248048 8 0>,
				<DCC_READ 0x9238030 1 0>,
				<DCC_READ 0x9238060 1 0>,
				<DCC_READ 0x9238064 1 0>,
				<DCC_READ 0x9238074 1 0>,
				<DCC_READ 0x9238088 1 0>,
				<DCC_READ 0x92380a0 1 0>,
				<DCC_READ 0x92380b0 1 0>,
				<DCC_READ 0x92a0344 8 0>,
				<DCC_READ 0x92a0370 6 0>,
				<DCC_READ 0x92a0480 1 0>,
				<DCC_READ 0x92a2400 1 0>,
				<DCC_READ 0x92a240c 1 0>,
				<DCC_READ 0x92a3214 2 0>,
				<DCC_READ 0x92a3220 3 0>,
				<DCC_READ 0x92a3308 1 0>,
				<DCC_READ 0x92a3318 1 0>,
				<DCC_READ 0x92b2100 1 0>,
				<DCC_READ 0x92b6040 6 0>,
				<DCC_READ 0x92b60b0 1 0>,
				<DCC_READ 0x92ba004 4 0>,
				<DCC_READ 0x92be030 2 0>,
				<DCC_READ 0x92c1000 1 0>,
				<DCC_READ 0x92c2028 1 0>,
				<DCC_READ 0x92c2044 3 0>,
				<DCC_READ 0x92c2070 1 0>,
				<DCC_READ 0x92c8030 1 0>,
				<DCC_READ 0x92c8048 8 0>,
				<DCC_READ 0x92b8030 1 0>,
				<DCC_READ 0x92b8060 1 0>,
				<DCC_READ 0x92b8064 1 0>,
				<DCC_READ 0x92b8074 1 0>,
				<DCC_READ 0x92b8088 1 0>,
				<DCC_READ 0x92b80a0 1 0>,
				<DCC_READ 0x92b80b0 1 0>,
				<DCC_READ 0x92c8064 1 0>,
				<DCC_READ 0x9270080 1 0>,
				<DCC_READ 0x9270310 1 0>,
				<DCC_READ 0x9270400 1 0>,
				<DCC_READ 0x9270410 6 0>,
				<DCC_READ 0x9270430 1 0>,
				<DCC_READ 0x9270440 1 0>,
				<DCC_READ 0x9270448 1 0>,
				<DCC_READ 0x92704a0 1 0>,
				<DCC_READ 0x92704b0 1 0>,
				<DCC_READ 0x92704b8 2 0>,
				<DCC_READ 0x92704d0 2 0>,
				<DCC_READ 0x9271400 1 0>,
				<DCC_READ 0x9271408 1 0>,
				<DCC_READ 0x927341c 1 0>,
				<DCC_READ 0x9273420 1 0>,
				<DCC_READ 0x92753b0 1 0>,
				<DCC_READ 0x9275804 1 0>,
				<DCC_READ 0x9275c18 2 0>,
				<DCC_READ 0x9275c2c 1 0>,
				<DCC_READ 0x9275c38 1 0>,
				<DCC_READ 0x9276418 2 0>,
				<DCC_READ 0x9279100 1 0>,
				<DCC_READ 0x9279110 1 0>,
				<DCC_READ 0x9279120 1 0>,
				<DCC_READ 0x9279180 2 0>,
				<DCC_READ 0x92f0080 1 0>,
				<DCC_READ 0x92f0310 1 0>,
				<DCC_READ 0x92f0400 1 0>,
				<DCC_READ 0x92f0410 6 0>,
				<DCC_READ 0x92f0430 1 0>,
				<DCC_READ 0x92f0440 1 0>,
				<DCC_READ 0x92f0448 1 0>,
				<DCC_READ 0x92f04a0 1 0>,
				<DCC_READ 0x92f04b0 1 0>,
				<DCC_READ 0x92f04b8 2 0>,
				<DCC_READ 0x92f04d0 2 0>,
				<DCC_READ 0x92f1400 1 0>,
				<DCC_READ 0x92f1408 1 0>,
				<DCC_READ 0x92f341c 1 0>,
				<DCC_READ 0x92f3420 1 0>,
				<DCC_READ 0x92f53b0 1 0>,
				<DCC_READ 0x92f5804 1 0>,
				<DCC_READ 0x92f5c18 2 0>,
				<DCC_READ 0x92f5c2c 1 0>,
				<DCC_READ 0x92f5c38 1 0>,
				<DCC_READ 0x92f6418 2 0>,
				<DCC_READ 0x92f9100 1 0>,
				<DCC_READ 0x92f9110 1 0>,
				<DCC_READ 0x92f9120 1 0>,
				<DCC_READ 0x92f9180 2 0>,
				<DCC_READ 0x9260080 1 0>,
				<DCC_READ 0x9260400 1 0>,
				<DCC_READ 0x9260410 3 0>,
				<DCC_READ 0x9260420 2 0>,
				<DCC_READ 0x9260430 1 0>,
				<DCC_READ 0x9260440 1 0>,
				<DCC_READ 0x9260448 1 0>,
				<DCC_READ 0x92604a0 1 0>,
				<DCC_READ 0x92604b0 1 0>,
				<DCC_READ 0x92604b8 2 0>,
				<DCC_READ 0x92604d0 2 0>,
				<DCC_READ 0x9261400 1 0>,
				<DCC_READ 0x9263410 1 0>,
				<DCC_READ 0x92653b0 1 0>,
				<DCC_READ 0x9265804 1 0>,
				<DCC_READ 0x9265b1c 1 0>,
				<DCC_READ 0x9265b2c 1 0>,
				<DCC_READ 0x9265b38 1 0>,
				<DCC_READ 0x9269100 1 0>,
				<DCC_READ 0x9269108 1 0>,
				<DCC_READ 0x9269110 1 0>,
				<DCC_READ 0x9269118 1 0>,
				<DCC_READ 0x9269120 1 0>,
				<DCC_READ 0x9269180 2 0>,
				<DCC_READ 0x92e0080 1 0>,
				<DCC_READ 0x92e0400 1 0>,
				<DCC_READ 0x92e0410 3 0>,
				<DCC_READ 0x92e0420 2 0>,
				<DCC_READ 0x92e0430 1 0>,
				<DCC_READ 0x92e0440 1 0>,
				<DCC_READ 0x92e0448 1 0>,
				<DCC_READ 0x92e04a0 1 0>,
				<DCC_READ 0x92e04b0 1 0>,
				<DCC_READ 0x92e04b8 2 0>,
				<DCC_READ 0x92e04d0 2 0>,
				<DCC_READ 0x92e1400 1 0>,
				<DCC_READ 0x92e3410 1 0>,
				<DCC_READ 0x92e53b0 1 0>,
				<DCC_READ 0x92e5804 1 0>,
				<DCC_READ 0x92e5b1c 1 0>,
				<DCC_READ 0x92e5b2c 1 0>,
				<DCC_READ 0x92e5b38 1 0>,
				<DCC_READ 0x92e9100 1 0>,
				<DCC_READ 0x92e9108 1 0>,
				<DCC_READ 0x92e9110 1 0>,
				<DCC_READ 0x92e9118 1 0>,
				<DCC_READ 0x92e9120 1 0>,
				<DCC_READ 0x92e9180 2 0>,
				<DCC_READ 0x96b0868 1 0>,
				<DCC_READ 0x96b0870 1 0>,
				<DCC_READ 0x96b1004 1 0>,
				<DCC_READ 0x96b100c 1 0>,
				<DCC_READ 0x96b1014 1 0>,
				<DCC_READ 0x96b1204 1 0>,
				<DCC_READ 0x96b120c 1 0>,
				<DCC_READ 0x96b1214 1 0>,
				<DCC_READ 0x96b1504 1 0>,
				<DCC_READ 0x96b150c 1 0>,
				<DCC_READ 0x96b1514 1 0>,
				<DCC_READ 0x96b1604 1 0>,
				<DCC_READ 0x96b8100 1 0>,
				<DCC_READ 0x96b813c 1 0>,
				<DCC_READ 0x96b8500 1 0>,
				<DCC_READ 0x96b853c 1 0>,
				<DCC_READ 0x96b8a04 1 0>,
				<DCC_READ 0x96b8a18 1 0>,
				<DCC_READ 0x96b8ea8 1 0>,
				<DCC_READ 0x96b9044 1 0>,
				<DCC_READ 0x96b904c 1 0>,
				<DCC_READ 0x96b9054 1 0>,
				<DCC_READ 0x96b905c 1 0>,
				<DCC_READ 0x96b910c 2 0>,
				<DCC_READ 0x96b9204 1 0>,
				<DCC_READ 0x96b920c 1 0>,
				<DCC_READ 0x96b9238 1 0>,
				<DCC_READ 0x96b9240 1 0>,
				<DCC_READ 0x96b926c 1 0>,
				<DCC_READ 0x96b9394 1 0>,
				<DCC_READ 0x96b939c 1 0>,
				<DCC_READ 0x96b9704 1 0>,
				<DCC_READ 0x96b970c 1 0>,
				<DCC_READ 0x96f0868 1 0>,
				<DCC_READ 0x96f0870 1 0>,
				<DCC_READ 0x96f1004 1 0>,
				<DCC_READ 0x96f100c 1 0>,
				<DCC_READ 0x96f1014 1 0>,
				<DCC_READ 0x96f1204 1 0>,
				<DCC_READ 0x96f120c 1 0>,
				<DCC_READ 0x96f1214 1 0>,
				<DCC_READ 0x96f1504 1 0>,
				<DCC_READ 0x96f150c 1 0>,
				<DCC_READ 0x96f1514 1 0>,
				<DCC_READ 0x96f1604 1 0>,
				<DCC_READ 0x96f8100 1 0>,
				<DCC_READ 0x96f813c 1 0>,
				<DCC_READ 0x96f8500 1 0>,
				<DCC_READ 0x96f853c 1 0>,
				<DCC_READ 0x96f8a04 1 0>,
				<DCC_READ 0x96f8a18 1 0>,
				<DCC_READ 0x96f8ea8 1 0>,
				<DCC_READ 0x96f9044 1 0>,
				<DCC_READ 0x96f904c 1 0>,
				<DCC_READ 0x96f9054 1 0>,
				<DCC_READ 0x96f905c 1 0>,
				<DCC_READ 0x96f910c 2 0>,
				<DCC_READ 0x96f9204 1 0>,
				<DCC_READ 0x96f920c 1 0>,
				<DCC_READ 0x96f9238 1 0>,
				<DCC_READ 0x96f9240 1 0>,
				<DCC_READ 0x96f926c 1 0>,
				<DCC_READ 0x96f9394 1 0>,
				<DCC_READ 0x96f939c 1 0>,
				<DCC_READ 0x96f9704 1 0>,
				<DCC_READ 0x96f970c 1 0>,
				<DCC_READ 0x9130100 3 0>,
				<DCC_READ 0x9170100 3 0>,
				<DCC_READ 0x91dd100 4 0>,
				<DCC_READ 0x91df100 1 0>,
				<DCC_READ 0x610110 5 0>,
				<DCC_READ 0x9230010 1 0>,
				<DCC_READ 0x9230020 1 0>,
				<DCC_READ 0x9230030 1 0>,
				<DCC_READ 0x9230040 1 0>,
				<DCC_READ 0x92b0010 1 0>,
				<DCC_READ 0x92b0020 1 0>,
				<DCC_READ 0x92b0030 1 0>,
				<DCC_READ 0x92b0040 1 0>,
				<DCC_READ 0x9232050 1 0>,
				<DCC_READ 0x923605c 2 0>,
				<DCC_READ 0x92360a0 1 0>,
				<DCC_READ 0x923a018 2 0>,
				<DCC_READ 0x92b2050 1 0>,
				<DCC_READ 0x92b605c 2 0>,
				<DCC_READ 0x92b60a0 1 0>,
				<DCC_READ 0x92ba018 2 0>,
				<DCC_READ 0x9222404 2 0>,
				<DCC_READ 0x9222410 1 0>,
				<DCC_READ 0x9238004 1 0>,
				<DCC_READ 0x9238014 1 0>,
				<DCC_READ 0x923805c 1 0>,
				<DCC_READ 0x923a014 1 0>,
				<DCC_READ 0x92a2404 2 0>,
				<DCC_READ 0x92a2410 1 0>,
				<DCC_READ 0x92b8004 1 0>,
				<DCC_READ 0x92b8014 1 0>,
				<DCC_READ 0x92b805c 1 0>,
				<DCC_READ 0x92ba014 1 0>,
				<DCC_WRITE 0x06e0a00c 0x00600007 1>,
				<DCC_WRITE 0x06e0a01c 0x00136800 1>,
				<DCC_READ 0x06e0a014 1 1>,
				<DCC_WRITE 0x06e0a01c 0x00136810 1>,
				<DCC_READ 0x06e0a014 1 1>,
				<DCC_WRITE 0x06e0a01c 0x00136820 1>,
				<DCC_READ 0x06e0a014 1 1>,
				<DCC_WRITE 0x06e0a01c 0x00136830 1>,
				<DCC_READ 0x06e0a014 1 1>,
				<DCC_WRITE 0x06e0a01c 0x00136840 1>,
				<DCC_READ 0x06e0a014 1 1>,
				<DCC_WRITE 0x06e0a01c 0x00136850 1>,
				<DCC_READ 0x06e0a014 1 1>,
				<DCC_WRITE 0x06e0a01c 0x00136860 1>,
				<DCC_READ 0x06e0a014 1 1>,
				<DCC_WRITE 0x06e0a01c 0x00136870 1>,
				<DCC_READ 0x06e0a014 1 1>,
				<DCC_WRITE 0x06e0a01c 0x0003e9a0 1>,
				<DCC_WRITE 0x06e0a01c 0x001368a0 1>,
				<DCC_READ 0x06e0a014 1 1>,
				<DCC_WRITE 0x06e0a01c 0x0003c0a0 1>,
				<DCC_WRITE 0x06e0a01c 0x001368a0 1>,
				<DCC_READ 0x06e0a014 1 1>,
				<DCC_WRITE 0x06e0a01c 0x0003d1a0 1>,
				<DCC_WRITE 0x06e0a01c 0x001368a0 1>,
				<DCC_READ 0x06e0a014 1 1>,
				<DCC_WRITE 0x06e0a01c 0x0003d2a0 1>,
				<DCC_WRITE 0x06e0a01c 0x001368a0 1>,
				<DCC_READ 0x06e0a014 1 1>,
				<DCC_WRITE 0x06e0a01c 0x0003d5a0 1>,
				<DCC_WRITE 0x06e0a01c 0x001368a0 1>,
				<DCC_READ 0x06e0a014 1 1>,
				<DCC_WRITE 0x06e0a01c 0x0003d6a0 1>,
				<DCC_WRITE 0x06e0a01c 0x001368a0 1>,
				<DCC_READ 0x06e0a014 1 1>,
				<DCC_WRITE 0x06e0a01c 0x0003e8a0 1>,
				<DCC_WRITE 0x06e0a01c 0x001368a0 1>,
				<DCC_READ 0x06e0a014 1 1>,
				<DCC_WRITE 0x06e0a01c 0x0003eea0 1>,
				<DCC_WRITE 0x06e0a01c 0x001368a0 1>,
				<DCC_READ 0x06e0a014 1 1>,
				<DCC_WRITE 0x06e0a01c 0x0003b1a0 1>,
				<DCC_WRITE 0x06e0a01c 0x001368a0 1>,
				<DCC_READ 0x06e0a014 1 1>,
				<DCC_WRITE 0x06e0a01c 0x0003b2a0 1>,
				<DCC_WRITE 0x06e0a01c 0x001368a0 1>,
				<DCC_READ 0x06e0a014 1 1>,
				<DCC_WRITE 0x06e0a01c 0x0003b5a0 1>,
				<DCC_WRITE 0x06e0a01c 0x001368a0 1>,
				<DCC_READ 0x06e0a014 1 1>,
				<DCC_WRITE 0x06e0a01c 0x0003b6a0 1>,
				<DCC_WRITE 0x06e0a01c 0x001368a0 1>,
				<DCC_READ 0x06e0a014 1 1>,
				<DCC_WRITE 0x06e0a01c 0x0003c2a0 1>,
				<DCC_WRITE 0x06e0a01c 0x001368a0 1>,
				<DCC_READ 0x06e0a014 1 1>,
				<DCC_WRITE 0x06e0a01c 0x0003c5a0 1>,
				<DCC_WRITE 0x06e0a01c 0x001368a0 1>,
				<DCC_READ 0x06e0a014 1 1>,
				<DCC_WRITE 0x06e0a01c 0x0003c6a0 1>,
				<DCC_WRITE 0x06e0a01c 0x001368a0 1>,
				<DCC_READ 0x06e0a014 1 1>,
				<DCC_WRITE 0x06e0a014 0x0002000c 1>,
				<DCC_WRITE 0x06e0a01c 0x000368b0 1>,
				<DCC_WRITE 0x06e0a01c 0x00000ba8 1>,
				<DCC_WRITE 0x06e0a01c 0x0013b6a0 1>,
				<DCC_WRITE 0x06e0a01c 0x00f1e000 1>,
				<DCC_WRITE 0x06e0a008 0x00000007 1>,
				<DCC_READ 0x09067e00 124 0>,
				<DCC_READ 0x905000c 1 0>,
				<DCC_READ 0x9050948 1 0>,
				<DCC_READ 0x9050078 1 0>,
				<DCC_READ 0x9050008 1 0>;
		};

		link_list3 {
			qcom,curr-link-list = <3>;
			qcom,data-sink = "sram";
			qcom,link-list = <DCC_READ 0xb2c4520 1 0>,
				<DCC_READ 0xb2c1020 2 0>,
				<DCC_READ 0xb2c1030 1 0>,
				<DCC_READ 0xb2c1200 1 0>,
				<DCC_READ 0xb2c1214 1 0>,
				<DCC_READ 0xb2c1228 1 0>,
				<DCC_READ 0xb2c123c 1 0>,
				<DCC_READ 0xb2c1250 1 0>,
				<DCC_READ 0xb2c1204 1 0>,
				<DCC_READ 0xb2c1218 1 0>,
				<DCC_READ 0xb2c122c 1 0>,
				<DCC_READ 0xb2c1240 1 0>,
				<DCC_READ 0xb2c1254 1 0>,
				<DCC_READ 0xb2c1208 1 0>,
				<DCC_READ 0xb2c121c 1 0>,
				<DCC_READ 0xb2c1230 1 0>,
				<DCC_READ 0xb2c1244 1 0>,
				<DCC_READ 0xb2c1258 1 0>,
				<DCC_READ 0xb2c4510 2 0>,
				<DCC_READ 0xb2c0010 2 0>,
				<DCC_READ 0xb2c0900 2 0>,
				<DCC_READ 0x04082028 1 0>,
				<DCC_READ 0x18a00c 1 0>,
				<DCC_READ 0x04080044 1 0>,
				<DCC_READ 0x04080304 1 0>,
				<DCC_READ 0x41a802c 1 0>,
				<DCC_READ 0x4200010 3 0>,
				<DCC_READ 0x4200030 1 0>,
				<DCC_READ 0x4200038 1 0>,
				<DCC_READ 0x4200040 1 0>,
				<DCC_READ 0x4200048 1 0>,
				<DCC_READ 0x42000d0 1 0>,
				<DCC_READ 0x4200210 1 0>,
				<DCC_READ 0x4200230 1 0>,
				<DCC_READ 0x4200250 1 0>,
				<DCC_READ 0x4200270 1 0>,
				<DCC_READ 0x4200290 1 0>,
				<DCC_READ 0x42002b0 1 0>,
				<DCC_READ 0x4200208 1 0>,
				<DCC_READ 0x4200228 1 0>,
				<DCC_READ 0x4200248 1 0>,
				<DCC_READ 0x4200268 1 0>,
				<DCC_READ 0x4200288 1 0>,
				<DCC_READ 0x42002a8 1 0>,
				<DCC_READ 0x420020c 1 0>,
				<DCC_READ 0x420022c 1 0>,
				<DCC_READ 0x420024c 1 0>,
				<DCC_READ 0x420026c 1 0>,
				<DCC_READ 0x420028c 1 0>,
				<DCC_READ 0x42002ac 1 0>,
				<DCC_READ 0x4200400 3 0>,
				<DCC_READ 0x4200d04 1 0>,
				<DCC_READ 0x4130010 3 0>,
				<DCC_READ 0x4130210 1 0>,
				<DCC_READ 0x4130230 1 0>,
				<DCC_READ 0x4130250 1 0>,
				<DCC_READ 0x4130270 1 0>,
				<DCC_READ 0x4130290 1 0>,
				<DCC_READ 0x41302b0 1 0>,
				<DCC_READ 0x4130208 1 0>,
				<DCC_READ 0x4130228 1 0>,
				<DCC_READ 0x4130248 1 0>,
				<DCC_READ 0x4130268 1 0>,
				<DCC_READ 0x4130288 1 0>,
				<DCC_READ 0x41302a8 1 0>,
				<DCC_READ 0x413020c 1 0>,
				<DCC_READ 0x413022c 1 0>,
				<DCC_READ 0x413024c 1 0>,
				<DCC_READ 0x413026c 1 0>,
				<DCC_READ 0x413028c 1 0>,
				<DCC_READ 0x41302ac 1 0>,
				<DCC_READ 0x4130400 3 0>,
				<DCC_READ 0xb254520 1 0>,
				<DCC_READ 0xb251020 2 0>,
				<DCC_READ 0xb251030 1 0>,
				<DCC_READ 0xb251200 1 0>,
				<DCC_READ 0xb251214 1 0>,
				<DCC_READ 0xb251228 1 0>,
				<DCC_READ 0xb25123c 1 0>,
				<DCC_READ 0xb251250 1 0>,
				<DCC_READ 0xb251204 1 0>,
				<DCC_READ 0xb251218 1 0>,
				<DCC_READ 0xb25122c 1 0>,
				<DCC_READ 0xb251240 1 0>,
				<DCC_READ 0xb251254 1 0>,
				<DCC_READ 0xb251208 1 0>,
				<DCC_READ 0xb25121c 1 0>,
				<DCC_READ 0xb251230 1 0>,
				<DCC_READ 0xb251244 1 0>,
				<DCC_READ 0xb251258 1 0>,
				<DCC_READ 0xb254510 2 0>,
				<DCC_READ 0xb250010 2 0>,
				<DCC_READ 0xb250900 2 0>,
				<DCC_READ 0x03002028 1 0>,
				<DCC_READ 0x03500010 3 0>,
				<DCC_READ 0x03500030 1 0>,
				<DCC_READ 0x03500038 1 0>,
				<DCC_READ 0x03500040 1 0>,
				<DCC_READ 0x03500048 1 0>,
				<DCC_READ 0x035000d0 1 0>,
				<DCC_READ 0x03500210 1 0>,
				<DCC_READ 0x03500230 1 0>,
				<DCC_READ 0x03500250 1 0>,
				<DCC_READ 0x03500270 1 0>,
				<DCC_READ 0x03500290 1 0>,
				<DCC_READ 0x035002b0 1 0>,
				<DCC_READ 0x03500208 1 0>,
				<DCC_READ 0x03500228 1 0>,
				<DCC_READ 0x03500248 1 0>,
				<DCC_READ 0x03500268 1 0>,
				<DCC_READ 0x03500288 1 0>,
				<DCC_READ 0x035002a8 1 0>,
				<DCC_READ 0x0350020c 1 0>,
				<DCC_READ 0x0350022c 1 0>,
				<DCC_READ 0x0350024c 1 0>,
				<DCC_READ 0x0350026c 1 0>,
				<DCC_READ 0x0350028c 1 0>,
				<DCC_READ 0x035002ac 1 0>,
				<DCC_READ 0x03500400 3 0>,
				<DCC_READ 0x03500d04 1 0>,
				<DCC_READ 0x030b0010 3 0>,
				<DCC_READ 0x030b0210 1 0>,
				<DCC_READ 0x030b0230 1 0>,
				<DCC_READ 0x030b0250 1 0>,
				<DCC_READ 0x030b0270 1 0>,
				<DCC_READ 0x030b0290 1 0>,
				<DCC_READ 0x030b02b0 1 0>,
				<DCC_READ 0x030b0208 1 0>,
				<DCC_READ 0x030b0228 1 0>,
				<DCC_READ 0x030b0248 1 0>,
				<DCC_READ 0x030b0268 1 0>,
				<DCC_READ 0x030b0288 1 0>,
				<DCC_READ 0x030b02a8 1 0>,
				<DCC_READ 0x030b020c 1 0>,
				<DCC_READ 0x030b022c 1 0>,
				<DCC_READ 0x030b024c 1 0>,
				<DCC_READ 0x030b026c 1 0>,
				<DCC_READ 0x030b028c 1 0>,
				<DCC_READ 0x030b02ac 1 0>,
				<DCC_READ 0x030b0400 3 0>,
				<DCC_READ 0xb2b4520 1 0>,
				<DCC_READ 0xb2b1020 2 0>,
				<DCC_READ 0xb2b1030 1 0>,
				<DCC_READ 0xb2b1200 1 0>,
				<DCC_READ 0xb2b1214 1 0>,
				<DCC_READ 0xb2b1228 1 0>,
				<DCC_READ 0xb2b123c 1 0>,
				<DCC_READ 0xb2b1250 1 0>,
				<DCC_READ 0xb2b1204 1 0>,
				<DCC_READ 0xb2b1218 1 0>,
				<DCC_READ 0xb2b122c 1 0>,
				<DCC_READ 0xb2b1240 1 0>,
				<DCC_READ 0xb2b1254 1 0>,
				<DCC_READ 0xb2b1208 1 0>,
				<DCC_READ 0xb2b121c 1 0>,
				<DCC_READ 0xb2b1230 1 0>,
				<DCC_READ 0xb2b1244 1 0>,
				<DCC_READ 0xb2b1258 1 0>,
				<DCC_READ 0xb2b4510 2 0>,
				<DCC_READ 0xb2b0010 1 0>,
				<DCC_READ 0xb2b0900 1 0>,
				<DCC_READ 0xa302028 1 0>,
				<DCC_READ 0xa0a4010 3 0>,
				<DCC_READ 0xa0a4030 1 0>,
				<DCC_READ 0xa0a4038 1 0>,
				<DCC_READ 0xa0a4040 2 0>,
				<DCC_READ 0xa0a40d0 1 0>,
				<DCC_READ 0xa0a4210 1 0>,
				<DCC_READ 0xa0a4230 1 0>,
				<DCC_READ 0xa0a4250 1 0>,
				<DCC_READ 0xa0a4270 1 0>,
				<DCC_READ 0xa0a4290 1 0>,
				<DCC_READ 0xa0a42b0 1 0>,
				<DCC_READ 0xa0a4208 1 0>,
				<DCC_READ 0xa0a4228 1 0>,
				<DCC_READ 0xa0a4248 1 0>,
				<DCC_READ 0xa0a4268 1 0>,
				<DCC_READ 0xa0a4288 1 0>,
				<DCC_READ 0xa0a42a8 1 0>,
				<DCC_READ 0xa0a420c 1 0>,
				<DCC_READ 0xa0a422c 1 0>,
				<DCC_READ 0xa0a424c 1 0>,
				<DCC_READ 0xa0a426c 1 0>,
				<DCC_READ 0xa0a428c 1 0>,
				<DCC_READ 0xa0a42ac 1 0>,
				<DCC_READ 0xa0a4400 2 0>,
				<DCC_READ 0xa0a4d04 1 0>,
				<DCC_READ 0xa3b0010 3 0>,
				<DCC_READ 0xa3b0210 1 0>,
				<DCC_READ 0xa3b0230 1 0>,
				<DCC_READ 0xa3b0250 1 0>,
				<DCC_READ 0xa3b0270 1 0>,
				<DCC_READ 0xa3b0290 1 0>,
				<DCC_READ 0xa3b02b0 1 0>,
				<DCC_READ 0xa3b0208 1 0>,
				<DCC_READ 0xa3b0228 1 0>,
				<DCC_READ 0xa3b0248 1 0>,
				<DCC_READ 0xa3b0268 1 0>,
				<DCC_READ 0xa3b0288 1 0>,
				<DCC_READ 0xa3b02a8 1 0>,
				<DCC_READ 0xa3b020c 1 0>,
				<DCC_READ 0xa3b022c 1 0>,
				<DCC_READ 0xa3b024c 1 0>,
				<DCC_READ 0xa3b026c 1 0>,
				<DCC_READ 0xa3b028c 1 0>,
				<DCC_READ 0xa3b02ac 1 0>,
				<DCC_READ 0xa3b0400 3 0>,
				<DCC_READ 0x3500d00 3 0>,
				<DCC_READ 0x3500d10 4 0>,
				<DCC_READ 0x3500fb0 4 0>,
				<DCC_READ 0x3501250 4 0>,
				<DCC_READ 0x35014f0 4 0>,
				<DCC_READ 0x3501790 4 0>,
				<DCC_READ 0x3501a30 4 0>,
				<DCC_READ 0x3503d44 4 0>,
				<DCC_READ 0x35000d0 3 0>,
				<DCC_READ 0x3500100 1 0>,
				<DCC_READ 0x3500d3c 1 0>,
				<DCC_READ 0xa0a40d0 3 0>,
				<DCC_READ 0xa0a4100 1 0>,
				<DCC_READ 0xa0a4d3c 1 0>,
				<DCC_READ 0xa0a7d44 4 0>,
				<DCC_READ 0xa0a4d00 3 0>,
				<DCC_READ 0x8a02028 1 0>,
				<DCC_READ 0x8b00000 1 0>,
				<DCC_READ 0x8b00004 1 0>,
				<DCC_READ 0x8b00010 1 0>,
				<DCC_READ 0x8b00014 1 0>,
				<DCC_READ 0x8b00018 1 0>,
				<DCC_READ 0x8b0001c 1 0>,
				<DCC_READ 0x8b00020 1 0>,
				<DCC_READ 0x8b00024 1 0>,
				<DCC_READ 0x8b00028 1 0>,
				<DCC_READ 0x8b0002c 1 0>,
				<DCC_READ 0x8b00030 1 0>,
				<DCC_READ 0x8b00034 1 0>,
				<DCC_READ 0x8b00038 1 0>,
				<DCC_READ 0x8b0003c 1 0>,
				<DCC_READ 0x8b00040 1 0>,
				<DCC_READ 0x8b00044 1 0>,
				<DCC_READ 0x8b00048 1 0>,
				<DCC_READ 0x8b000d0 1 0>,
				<DCC_READ 0x8b000d8 1 0>,
				<DCC_READ 0x8b00100 1 0>,
				<DCC_READ 0x8b00104 1 0>,
				<DCC_READ 0x8b00108 1 0>,
				<DCC_READ 0x8b00200 1 0>,
				<DCC_READ 0x8b00204 1 0>,
				<DCC_READ 0x8b00224 1 0>,
				<DCC_READ 0x8b00244 1 0>,
				<DCC_READ 0x8b00264 1 0>,
				<DCC_READ 0x8b00284 1 0>,
				<DCC_READ 0x8b002a4 1 0>,
				<DCC_READ 0x8b00208 1 0>,
				<DCC_READ 0x8b00228 1 0>,
				<DCC_READ 0x8b00248 1 0>,
				<DCC_READ 0x8b00268 1 0>,
				<DCC_READ 0x8b00288 1 0>,
				<DCC_READ 0x8b002a8 1 0>,
				<DCC_READ 0x8b0020c 1 0>,
				<DCC_READ 0x8b0022c 1 0>,
				<DCC_READ 0x8b0024c 1 0>,
				<DCC_READ 0x8b0026c 1 0>,
				<DCC_READ 0x8b0028c 1 0>,
				<DCC_READ 0x8b002ac 1 0>,
				<DCC_READ 0x8b00210 1 0>,
				<DCC_READ 0x8b00230 1 0>,
				<DCC_READ 0x8b00250 1 0>,
				<DCC_READ 0x8b00270 1 0>,
				<DCC_READ 0x8b00290 1 0>,
				<DCC_READ 0x8b002b0 1 0>,
				<DCC_READ 0x8b00400 1 0>,
				<DCC_READ 0x8b00404 1 0>,
				<DCC_READ 0x8b00408 1 0>,
				<DCC_READ 0x8b00460 1 0>,
				<DCC_READ 0x8b00464 1 0>,
				<DCC_READ 0x8b004a0 1 0>,
				<DCC_READ 0x8b004a4 1 0>,
				<DCC_READ 0x8b004a8 1 0>,
				<DCC_READ 0x8b004ac 1 0>,
				<DCC_READ 0x8b004b0 1 0>,
				<DCC_READ 0x8b004b4 1 0>,
				<DCC_READ 0x8b004b8 1 0>,
				<DCC_READ 0x8ab0000 1 0>,
				<DCC_READ 0x8ab0004 1 0>,
				<DCC_READ 0x8ab0010 1 0>,
				<DCC_READ 0x8ab0014 1 0>,
				<DCC_READ 0x8ab0018 1 0>,
				<DCC_READ 0x8ab00d0 1 0>,
				<DCC_READ 0x8ab00d8 1 0>,
				<DCC_READ 0x8ab0100 1 0>,
				<DCC_READ 0x8ab0104 1 0>,
				<DCC_READ 0x8ab0108 1 0>,
				<DCC_READ 0x8ab0200 1 0>,
				<DCC_READ 0x8ab0204 1 0>,
				<DCC_READ 0x8ab0224 1 0>,
				<DCC_READ 0x8ab0244 1 0>,
				<DCC_READ 0x8ab0264 1 0>,
				<DCC_READ 0x8ab0284 1 0>,
				<DCC_READ 0x8ab02a4 1 0>,
				<DCC_READ 0x8ab0208 1 0>,
				<DCC_READ 0x8ab0228 1 0>,
				<DCC_READ 0x8ab0248 1 0>,
				<DCC_READ 0x8ab0268 1 0>,
				<DCC_READ 0x8ab0288 1 0>,
				<DCC_READ 0x8ab02a8 1 0>,
				<DCC_READ 0x8ab020c 1 0>,
				<DCC_READ 0x8ab022c 1 0>,
				<DCC_READ 0x8ab024c 1 0>,
				<DCC_READ 0x8ab026c 1 0>,
				<DCC_READ 0x8ab028c 1 0>,
				<DCC_READ 0x8ab02ac 1 0>,
				<DCC_READ 0x8ab0210 1 0>,
				<DCC_READ 0x8ab0230 1 0>,
				<DCC_READ 0x8ab0250 1 0>,
				<DCC_READ 0x8ab0270 1 0>,
				<DCC_READ 0x8ab0290 1 0>,
				<DCC_READ 0x8ab02b0 1 0>,
				<DCC_READ 0x8ab0400 1 0>,
				<DCC_READ 0x8ab0404 1 0>,
				<DCC_READ 0x8ab0408 1 0>,
				<DCC_READ 0x8ab0460 1 0>,
				<DCC_READ 0x8ab0464 1 0>,
				<DCC_READ 0x8ab04a0 1 0>,
				<DCC_READ 0x8ab04a4 1 0>,
				<DCC_READ 0x8ab04a8 1 0>,
				<DCC_READ 0x8ab04ac 1 0>,
				<DCC_READ 0x8ab04b0 1 0>,
				<DCC_READ 0x8ab04b4 1 0>,
				<DCC_READ 0x8ab04b8 1 0>,
				<DCC_READ 0xaa10504 1 0>,
				<DCC_READ 0xaa10508 1 0>,
				<DCC_READ 0xaa10510 1 0>,
				<DCC_READ 0xaa10520 1 0>,
				<DCC_READ 0xaa10524 1 0>,
				<DCC_READ 0xaa10528 1 0>,
				<DCC_READ 0xaa1052c 1 0>,
				<DCC_READ 0xaa10530 1 0>,
				<DCC_READ 0xaa10534 1 0>,
				<DCC_READ 0xaa10538 1 0>,
				<DCC_READ 0xaa1053c 1 0>,
				<DCC_READ 0xaa10300 1 0>,
				<DCC_READ 0xaa10010 1 0>,
				<DCC_READ 0xaa10020 1 0>;
		};
	};

	mem_dump {
		compatible = "qcom,mem-dump";
		memory-region = <&dump_mem>;

		static_mem_dump {
			qcom,static-mem-dump;

			c0_context {
				qcom,dump-size = <0x800>;
				qcom,dump-id = <0x0>;
			};

			c100_context {
				qcom,dump-size = <0x800>;
				qcom,dump-id = <0x1>;
			};

			c200_context {
				qcom,dump-size = <0x800>;
				qcom,dump-id = <0x2>;
			};

			c300_context {
				qcom,dump-size = <0x800>;
				qcom,dump-id = <0x3>;
			};

			c400_context {
				qcom,dump-size = <0x800>;
				qcom,dump-id = <0x4>;
			};

			c500_context {
				qcom,dump-size = <0x800>;
				qcom,dump-id = <0x5>;
			};

			c600_context {
				qcom,dump-size = <0x800>;
				qcom,dump-id = <0x6>;
			};

			c700_context {
				qcom,dump-size = <0x800>;
				qcom,dump-id = <0x7>;
			};

			c0_scandump {
				qcom,dump-size = <0x10100>;
				qcom,dump-id = <0x130>;
			};

			c100_scandump {
				qcom,dump-size = <0x10100>;
				qcom,dump-id = <0x131>;
			};

			c200_scandump {
				qcom,dump-size = <0x10100>;
				qcom,dump-id = <0x132>;
			};

			c300_scandump {
				qcom,dump-size = <0x10100>;
				qcom,dump-id = <0x133>;
			};

			c400_scandump {
				qcom,dump-size = <0x40000>;
				qcom,dump-id = <0x134>;
			};

			c500_scandump {
				qcom,dump-size = <0x40000>;
				qcom,dump-id = <0x135>;
			};

			c600_scandump {
				qcom,dump-size = <0x40000>;
				qcom,dump-id = <0x136>;
			};

			c700_scandump {
				qcom,dump-size = <0x40000>;
				qcom,dump-id = <0x137>;
			};

			gemnoc {
				qcom,dump-size = <0x100000>;
				qcom,dump-id = <0x162>;
			};

			mhm_scan {
				qcom,dump-size = <0x20000>;
				qcom,dump-id = <0x161>;
			};

			rpmh {
				qcom,dump-size = <0x2000000>;
				qcom,dump-id = <0xec>;
			};

			rpm_sw {
				qcom,dump-size = <0x28000>;
				qcom,dump-id = <0xea>;
			};

			pmic {
				qcom,dump-size = <0x200000>;
				qcom,dump-id = <0xe4>;
			};

			fcm {
				qcom,dump-size = <0x8400>;
				qcom,dump-id = <0xee>;
			};

			etf_swao {
				qcom,dump-size = <0x10000>;
				qcom,dump-id = <0xf1>;
			};

			etr_reg {
				qcom,dump-size = <0x1000>;
				qcom,dump-id = <0x100>;
			};

			etfswao_reg {
				qcom,dump-size = <0x1000>;
				qcom,dump-id = <0x102>;
			};

			misc_data {
				qcom,dump-size = <0x1000>;
				qcom,dump-id = <0xe8>;
			};

			etf_lpass {
				qcom,dump-size = <0x4000>;
				qcom,dump-id = <0xf4>;
			};

			etflpass_reg {
				qcom,dump-size = <0x1000>;
				qcom,dump-id = <0x104>;
			};

			osm_reg {
				qcom,dump-size = <0x400>;
				qcom,dump-id = <0x163>;
			};

			pcu_reg {
				qcom,dump-size = <0x400>;
				qcom,dump-id = <0x164>;
			};

			fsm_data {
				qcom,dump-size = <0x400>;
				qcom,dump-id = <0x165>;
			};
		};

		dynamic_mem_dump {
			qcom,dynamic-mem-dump;

			cpuss_reg {
				cpuss_reg {
					qcom,dump-size = <0x30000>;
					qcom,dump-id = <0xef>;
				};
			};

			l1 {
				l1_icache0 {
					qcom,dump-size = <0x10900>;
					qcom,dump-id = <0x60>;
				};

				l1_icache100 {
					qcom,dump-size = <0x10900>;
					qcom,dump-id = <0x61>;
				};

				l1_icache200 {
					qcom,dump-size = <0x10900>;
					qcom,dump-id = <0x62>;
				};

				l1_icache300 {
					qcom,dump-size = <0x10900>;
					qcom,dump-id = <0x63>;
				};

				l1_icache400 {
					qcom,dump-size = <0x15100>;
					qcom,dump-id = <0x64>;
				};

				l1_icache500 {
					qcom,dump-size = <0x15100>;
					qcom,dump-id = <0x65>;
				};

				l1_icache600 {
					qcom,dump-size = <0x15100>;
					qcom,dump-id = <0x66>;
				};

				l1_icache700 {
					qcom,dump-size = <0x32100>;
					qcom,dump-id = <0x67>;
				};

				l1_dcache0 {
					qcom,dump-size = <0x9100>;
					qcom,dump-id = <0x80>;
				};

				l1_dcache100 {
					qcom,dump-size = <0x9100>;
					qcom,dump-id = <0x81>;
				};

				l1_dcache200 {
					qcom,dump-size = <0x9100>;
					qcom,dump-id = <0x82>;
				};

				l1_dcache300 {
					qcom,dump-size = <0x9100>;
					qcom,dump-id = <0x83>;
				};

				l1_dcache400 {
					qcom,dump-size = <0x9100>;
					qcom,dump-id = <0x84>;
				};

				l1_dcache500 {
					qcom,dump-size = <0x9100>;
					qcom,dump-id = <0x85>;
				};

				l1_dcache600 {
					qcom,dump-size = <0x9100>;
					qcom,dump-id = <0x86>;
				};

				l1_dcache700 {
					qcom,dump-size = <0x12100>;
					qcom,dump-id = <0x87>;
				};

				l1_itlb400 {
					qcom,dump-size = <0x300>;
					qcom,dump-id = <0x24>;
				};

				l1_itlb500 {
					qcom,dump-size = <0x300>;
					qcom,dump-id = <0x25>;
				};

				l1_itlb600 {
					qcom,dump-size = <0x300>;
					qcom,dump-id = <0x26>;
				};

				l1_itlb700 {
					qcom,dump-size = <0x400>;
					qcom,dump-id = <0x27>;
				};

				l1_dtlb400 {
					qcom,dump-size = <0x300>;
					qcom,dump-id = <0x44>;
				};

				l1_dtlb500 {
					qcom,dump-size = <0x300>;
					qcom,dump-id = <0x45>;
				};

				l1_dtlb600 {
					qcom,dump-size = <0x300>;
					qcom,dump-id = <0x46>;
				};

				l1_dtlb700 {
					qcom,dump-size = <0x3a0>;
					qcom,dump-id = <0x47>;
				};
			};

			l2 {
				l2_cache400 {
					qcom,dump-size = <0x90100>;
					qcom,dump-id = <0xc4>;
				};

				l2_cache500 {
					qcom,dump-size = <0x90100>;
					qcom,dump-id = <0xc5>;
				};

				l2_cache600 {
					qcom,dump-size = <0x90100>;
					qcom,dump-id = <0xc6>;
				};

				l2_cache700 {
					qcom,dump-size = <0x120100>;
					qcom,dump-id = <0xc7>;
				};

				l2_tlb0 {
					qcom,dump-size = <0x5b00>;
					qcom,dump-id = <0x120>;
				};

				l2_tlb100 {
					qcom,dump-size = <0x5b00>;
					qcom,dump-id = <0x121>;
				};

				l2_tlb200 {
					qcom,dump-size = <0x5b00>;
					qcom,dump-id = <0x122>;
				};

				l2_tlb300 {
					qcom,dump-size = <0x5b00>;
					qcom,dump-id = <0x123>;
				};

				l2_tlb400 {
					qcom,dump-size = <0x6100>;
					qcom,dump-id = <0x124>;
				};

				l2_tlb500 {
					qcom,dump-size = <0x6100>;
					qcom,dump-id = <0x125>;
				};

				l2_tlb600 {
					qcom,dump-size = <0x6100>;
					qcom,dump-id = <0x126>;
				};

				l2_tlb700 {
					qcom,dump-size = <0xc100>;
					qcom,dump-id = <0x127>;
				};
			};

			LLCC_1 {
				llcc_1_dcache {
					qcom,dump-size = <0x1141c0>;
					qcom,dump-id = <0x140>;
				};
			};

			LLCC_2 {
				llcc_2_dcache {
					qcom,dump-size = <0x1141c0>;
					qcom,dump-id = <0x141>;
				};
			};
		};
	};
};
